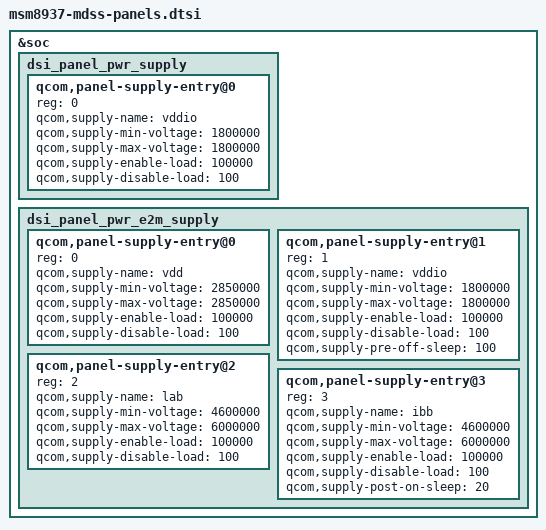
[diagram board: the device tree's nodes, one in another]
/* Copyright (c) 2015-2017, The Linux Foundation. All rights reserved.
 *
 * This program is free software; you can redistribute it and/or modify
 * it under the terms of the GNU General Public License version 2 and
 * only version 2 as published by the Free Software Foundation.
 *
 * This program is distributed in the hope that it will be useful,
 * but WITHOUT ANY WARRANTY; without even the implied warranty of
 * MERCHANTABILITY or FITNESS FOR A PARTICULAR PURPOSE.  See the
 * GNU General Public License for more details.
 */

#include "dsi-panel-sim-video.dtsi"
#include "dsi-panel-sim-cmd.dtsi"
#include "dsi-panel-truly-1080p-video.dtsi"
#include "dsi-panel-truly-1080p-cmd.dtsi"
#include "dsi-panel-r69006-1080p-cmd.dtsi"
#include "dsi-panel-r69006-1080p-video.dtsi"
#include "dsi-panel-hx8394f-720p-video.dtsi"
#include "dsi-adv7533-1080p.dtsi"
#include "dsi-adv7533-720p.dtsi"
#include "dsi-panel-truly-720p-video.dtsi"
#include "dsi-panel-truly-wuxga-video.dtsi"
#include "dsi-panel-truly-720p-cmd.dtsi"
#include "dsi-panel-lead-fl10802-fwvga-video.dtsi"
#include "dsi-panel-icn9706-720-1440p-video.dtsi"
#include "components/display/dsi-panel-r61322-1080p-video.dtsi" //Fihtdc,Add for MS3
#include "components/display/dsi-panel-fih-ili7807e-1080p-video.dtsi" //SW4-HL-Display-BringUpILI7807E-00+_20160725
#include "components/display/dsi-panel-fih-hx8394a-720p-video.dtsi"
#include "components/display/dsi-panel-fih-nt35521-720p-video.dtsi"
#include "components/display/dsi-panel-fih-nt35521s-720p-video.dtsi"	//SW4-HL-Display-BringUpNT35521S-00+_20160920
#include "components/display/dsi-panel-pj050ia-nt35521s-720p-video.dtsi" //SW8-AC-Display-Bringup-00
#include "components/display/dsi-panel-sharp-ft8607-720p-video-OC6.dtsi" //OC6 panel
#include "components/display/dsi-panel-ili9881c-720p-video-hlt.dtsi"
#include "components/display/dsi-panel-ili9881c-720p-video-inno.dtsi"
#include "components/display/dsi-panel-otm1290a-720p-video-hlt-evt.dtsi"
#include "components/display/dsi-panel-otm1290a-720p-video-txd-evt.dtsi"
#include "components/display/dsi-panel-otm1290a-720p-video.dtsi"

&soc {
	dsi_panel_pwr_supply: dsi_panel_pwr_supply {
		#address-cells = <1>;
		#size-cells = <0>;

		/* SW4-HL-Display-BringUpILI7807E-00*{_20160725 */
		/* LDO17 is not used by lcm */
		/*
		qcom,panel-supply-entry@0 {
			reg = <0>;
			qcom,supply-name = "vdd";
			qcom,supply-min-voltage = <2850000>;
			qcom,supply-max-voltage = <2850000>;
			qcom,supply-enable-load = <100000>;
			qcom,supply-disable-load = <100>;
		};
		*/

		qcom,panel-supply-entry@0 {
			reg = <0>;
			qcom,supply-name = "vddio";
			qcom,supply-min-voltage = <1800000>;
			qcom,supply-max-voltage = <1800000>;
			qcom,supply-enable-load = <100000>;
			qcom,supply-disable-load = <100>;
		};
		/* SW4-HL-Display-BringUpILI7807E-00*}_20160725 */
	};

	dsi_panel_pwr_e2m_supply: dsi_panel_pwr_e2m_supply {
	#address-cells = <1>;
	#size-cells = <0>;

		qcom,panel-supply-entry@0 {
			reg = <0>;
			qcom,supply-name = "vdd";
			qcom,supply-min-voltage = <2850000>;
			qcom,supply-max-voltage = <2850000>;
			qcom,supply-enable-load = <100000>;
			qcom,supply-disable-load = <100>;
		};

		qcom,panel-supply-entry@1 {
			reg = <1>;
			qcom,supply-name = "vddio";
			qcom,supply-min-voltage = <1800000>;
			qcom,supply-max-voltage = <1800000>;
			qcom,supply-enable-load = <100000>;
			qcom,supply-disable-load = <100>;
			qcom,supply-pre-off-sleep = <100>;
		};

		qcom,panel-supply-entry@2 {
			reg = <2>;
			qcom,supply-name = "lab";
			qcom,supply-min-voltage = <4600000>;
			qcom,supply-max-voltage = <6000000>;
			qcom,supply-enable-load = <100000>;
			qcom,supply-disable-load = <100>;
		};

		qcom,panel-supply-entry@3 {
			reg = <3>;
			qcom,supply-name = "ibb";
			qcom,supply-min-voltage = <4600000>;
			qcom,supply-max-voltage = <6000000>;
			qcom,supply-enable-load = <100000>;
			qcom,supply-disable-load = <100>;
			qcom,supply-post-on-sleep = <20>;
		};
	};

};
